# TLE986x register map
Vendor: Infineon; File version: 3.7
CPU: CM3 r0p0, little endian, no MPU, no FPU, 4 interrupt priority bits
Registers are 32-bit, read-write, reset 0x0 unless marked. A register's access mark holds for its fields unless they carry their own. Offsets are from the block's base; [hi:lo] are bit positions; {n}, {i} and the like mark numbered series; 'fields as' and 'values as' point back to an identical list.

## MF — Measurement Function
Base 0x48018000
0x00 P2_ADCSEL_CTRL — Port 2 ADC Selection Control Register
  [10] ADC1_CH1_SEL — ADC1 Channel 1 Input Selection
    1=CS_AMP (Current Sense Amplifier is conncted to Ch1 of ADC1)
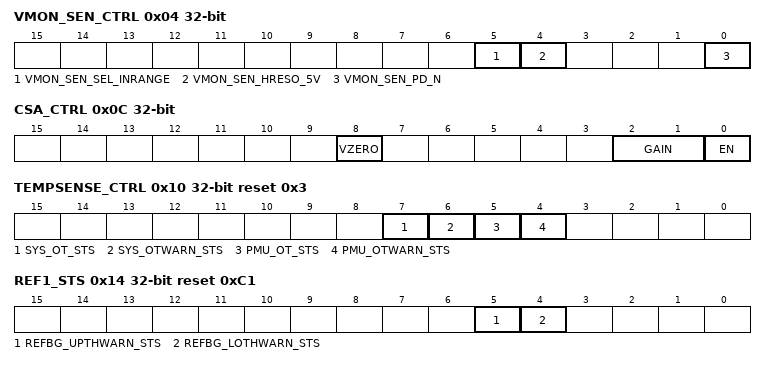
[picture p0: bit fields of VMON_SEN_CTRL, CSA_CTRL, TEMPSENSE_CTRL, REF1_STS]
0x04 VMON_SEN_CTRL — Supply Sense Control Register
  [5] VMON_SEN_SEL_INRANGE — Monitoring Input Attenuator Select Inputrange
    0=range0 (0-18V range is selected); 1=range1 (0-28V range is selected)
  [4] VMON_SEN_HRESO_5V — Monitoring Input Attenuator High Impedance Output Control
    0=High_Resistive_Output_Disable (Connection to ADC input low ohmic); 1=High_Resistive_Output_Enable (Connection to ADC input high ohmic)
  [0] VMON_SEN_PD_N — Monitoring Input Attenuator enable
    0=DISABLE (Attenuator switched off); 1=ENABLE (Attenuator switched on)
0x0C CSA_CTRL — Current Sense Amplifier Control Register
  [8] VZERO — Current Sense Output Voltage Level to Ground
    0=VOUT (Output Voltage is VOUT of Amplifier); 1=GROUND (Output Voltage is Ground of Feedback Network)
  [2:1] GAIN — OPA gain setting
    0=Gain_10; 1=Gain_20; 2=Gain_40; 3=Gain_60
  [0] EN — OPA enable
    0=DISABLE (OPA switched off); 1=ENABLE (OPA switched on)
0x10 TEMPSENSE_CTRL ro reset 0x3 — Temperature Sensor Control Register
  [all] fields
    0=INACTIVE (write clears status); 1=ACTIVE (interrupt status set)
  [7] SYS_OT_STS — System Overtemperature (MU) Status
  [6] SYS_OTWARN_STS — System Overtemperature Warning (MU) Status
  [5] PMU_OT_STS — PMU Regulator Overtemperature (MU) Status
  [4] PMU_OTWARN_STS — PMU Regulator Overtemperature Warning (MU) Status
0x14 REF1_STS ro reset 0xC1 — Reference 1 Status Register
  [5] REFBG_UPTHWARN_STS — Status for Overvoltage Threshold Measurement of internal VAREF
    0=UPPER_TRIG_RESET (write clears status); 1=UPPER_TRIG_SET (trigger status set)
  [4] REFBG_LOTHWARN_STS — Status for Undervoltage Threshold Measurement of internal VAREF
    values as REFBG_UPTHWARN_STS
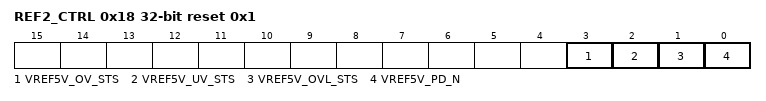
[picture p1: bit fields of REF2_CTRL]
0x18 REF2_CTRL access per field reset 0x1 — Reference 2 Control Register
  [3] VREF5V_OV_STS ro — ADC1 Bit Reference Voltage Generation Overvoltage Bit
    0=no Overvoltage detected; 1=Overvoltage detected
  [2] VREF5V_UV_STS ro — ADC1 Bit Reference Voltage Generation Undervoltage Bit
    0=no Undervoltage detected; 1=Undervoltage detected
  [1] VREF5V_OVL_STS ro — ADC1 Bit Reference Voltage Generation Over Load Bit
    0=no OVERLOAD detected; 1=OVERLOAD (OVERLOAD detected)
  [0] VREF5V_PD_N rw — ADC1 Bit Reference Voltage Generation Power Down Bit
    0=DISABLED (Power Down); 1=ACTIVE (no Power Down)

## PORT — GPIO PORTs
Base 0x48028000
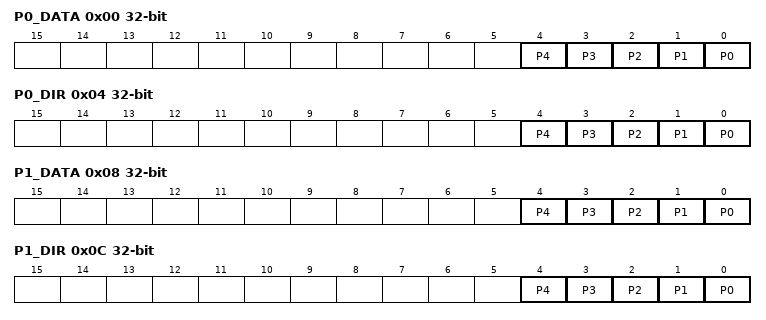
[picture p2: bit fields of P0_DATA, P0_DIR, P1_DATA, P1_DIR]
0x00 P0_DATA reset not defined — Port 0 Data Register
  [all] fields
    0=Port 0 pin n data value = 0; 1=Port 0 pin n data value = 1
  [n] P{n} (n=0..4) — Port 0 Pin {n} Data Value
0x04 P0_DIR — Port 0 Direction Register
  [all] fields
    0=Direction is set to input (default); 1=Direction is set to output
  [n] P{n} (n=0..4) — Port 0 Pin {n} Direction Control
0x08 P1_DATA reset not defined — Port 1 Data Register
  [all] fields
    0=Port 1 pin n data value = 0; 1=Port 1 pin n data value = 1
  [n] P{n} (n=0..4) — Port 1 Pin {n} Data Value
0x0C P1_DIR — Port 1 Direction Register
  [all] fields
    values as the fields of P0_DIR
  [n] P{n} (n=0..4) — Port 1 Pin {n} Direction Control
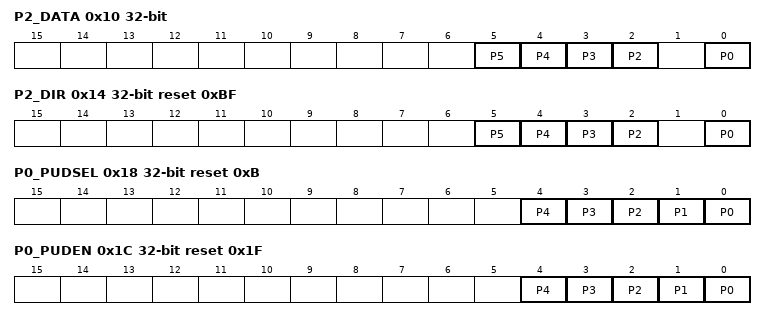
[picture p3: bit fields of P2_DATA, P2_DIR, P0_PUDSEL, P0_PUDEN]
0x10 P2_DATA ro reset not defined — Port 2 Data Register
  [all] fields
    0=Port 2 pin n data value = 0; 1=Port 2 pin n data value = 1
  [n] P{n} (n=2..5) — Port 2 Pin {n} Data Value
  [0] P0 — Port 2 Pin 0 Data Value
0x14 P2_DIR reset 0xBF — Port 2 Direction Register
  [all] fields
    0=Input driver is enabled; 1=Input driver is disabled (default)
  [n] P{n} (n=2..5) — Port 2 Pin {n} Driver Control
  [0] P0 — Port 2 Pin 0 Driver Control
0x18 P0_PUDSEL reset 0xB — Port 0 Pull-Up/Pull-Down Select Register
  [all] fields
    0=Pull-down device is selected; 1=Pull-up device is selected
  [n] P{n} (n=0..4) — Pull-Up/Pull-Down Select Port 0 Bit {n}
0x1C P0_PUDEN reset 0x1F — Port 0 Pull-Up/Pull-Down Enable Register
  [all] fields
    0=Pull-up or Pull-down device is disabled; 1=Pull-up or Pull-down device is enabled
  [n] P{n} (n=0..4) — Pull-Up/Pull-Down Enable at Port 0 Bit {n}
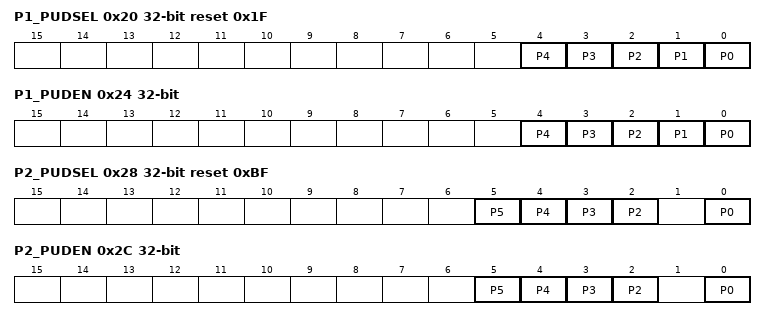
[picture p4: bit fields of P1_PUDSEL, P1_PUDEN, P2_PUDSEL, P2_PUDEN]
0x20 P1_PUDSEL reset 0x1F — Port 1 Pull-Up/Pull-Down Select Register
  [all] fields
    0=Pull-down device is selected; 1=Pull-up device is selected (default)
  [n] P{n} (n=0..4) — Pull-Up/Pull-Down Select Port 1 Bit {n}
0x24 P1_PUDEN — Port 1 Pull-Up/Pull-Down Enable Register
  [all] fields
    0=Pull-up or Pull-down device is disabled (default); 1=Pull-up or Pull-down device is enabled
  [n] P{n} (n=0..4) — Pull-Up/Pull-Down Enable at Port 1 Bit {n}
0x28 P2_PUDSEL reset 0xBF — Port 2 Pull-Up/Pull-Down Select Register
  [all] fields
    values as the fields of P1_PUDSEL
  [n] P{n} (n=2..5) — Pull-Up/Pull-Down Select Port 2 Bit {n}
  [0] P0 — Pull-Up/Pull-Down Select Port 2 Bit 0
0x2C P2_PUDEN — Port 2 Pull-Up/Pull-Down Enable Register
  [all] fields
    values as the fields of P1_PUDEN
  [n] P{n} (n=2..5) — Pull-Up/Pull-Down Enable at Port 2 Bit {n}
  [0] P0 — Pull-Up/Pull-Down Enable at Port 2 Bit 0
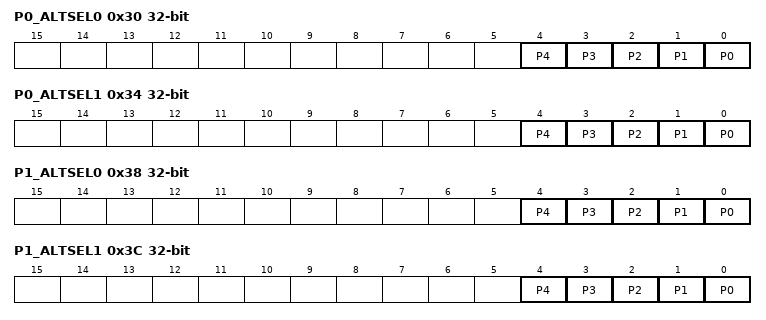
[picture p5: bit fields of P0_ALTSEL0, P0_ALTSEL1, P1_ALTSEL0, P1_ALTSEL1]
0x30 P0_ALTSEL0 — Port 0 Alternate Select Register
  [n] P{n} (n=0..4) — Alternate Select Port 0 Bit {n}
0x34 P0_ALTSEL1 — Port 0 Alternate Select Register
  [n] P{n} (n=0..4) — Alternate Select Port 0 Bit {n}
0x38 P1_ALTSEL0 — Port 1 Alternate Select Register
  [n] P{n} (n=0..4) — Alternate Select Port 1 Bit {n}
0x3C P1_ALTSEL1 — Port 1 Alternate Select Register
  [n] P{n} (n=0..4) — Alternate Select Port 1 Bit {n}
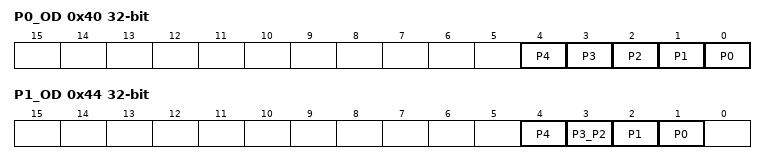
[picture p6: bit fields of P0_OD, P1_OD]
0x40 P0_OD — Port 0 Open Drain Control Register
  [all] fields
    0=Normal Mode, output is actively driven for 0 and 1 state (default); 1=Open Drain Mode, output is actively driven only for 0 state
  [n] P{n} (n=0..4) — Port 0 Pin {n} Open Drain Mode
0x44 P1_OD — Port 1 Open Drain Control Register
  [all] fields
    values as the fields of P0_OD
  [4] P4 — P1.4 Open Drain Mode
  [3] P3_P2 — P1.3/P1.2 Open Drain Mode
  [2] P1 — P1.1 Open Drain Mode
  [1] P0 — P1.0 Open Drain Mode
